# RZ/A1H register map
Vendor: Renesas
Registers are 32-bit, read-write, reset 0x0 unless marked. A register's access mark holds for its fields unless they carry their own. Offsets are from the block's base; [hi:lo] are bit positions; {n}, {i} and the like mark numbered series; 'fields as' and 'values as' point back to an identical list.

## INTC
Base 0xE8201000
0x00 ICDDCR
  [0] Enable
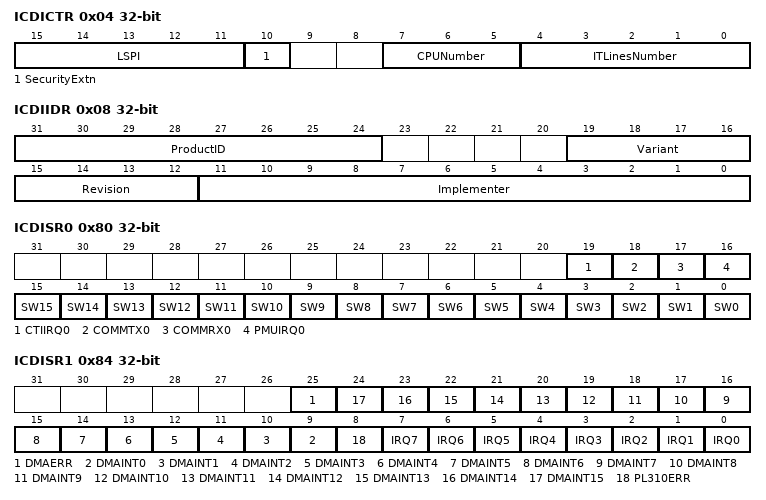
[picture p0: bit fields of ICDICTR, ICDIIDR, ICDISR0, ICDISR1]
0x04 ICDICTR
  [15:11] LSPI, [10] SecurityExtn, [7:5] CPUNumber, [4:0] ITLinesNumber
0x08 ICDIIDR
  [31:24] ProductID, [19:16] Variant, [15:12] Revision, [11:0] Implementer
0x80 ICDISR0
  [19] CTIIRQ0, [18] COMMTX0, [17] COMMRX0, [16] PMUIRQ0, [n] SW{n} (n=0..15)
0x84 ICDISR1
  [25] DMAERR, [n+9] DMAINT{n} (n=0..15), [8] PL310ERR, [n] IRQ{n} (n=0..7)
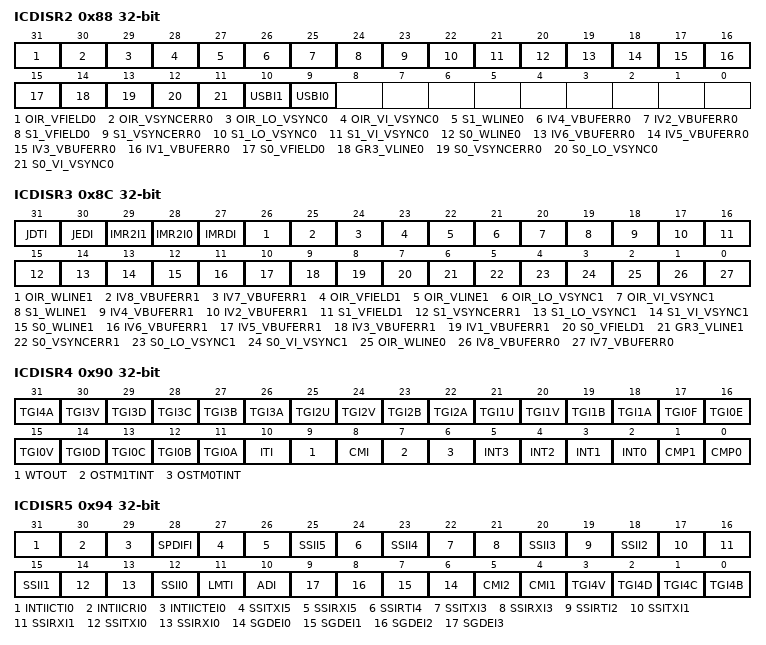
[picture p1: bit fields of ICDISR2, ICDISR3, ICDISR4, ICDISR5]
0x88 ICDISR2
  [31] OIR_VFIELD0, [30] OIR_VSYNCERR0, [29] OIR_LO_VSYNC0, [28] OIR_VI_VSYNC0, [27] S1_WLINE0, [26] IV4_VBUFERR0, [25] IV2_VBUFERR0, [24] S1_VFIELD0, [23] S1_VSYNCERR0, [22] S1_LO_VSYNC0, [21] S1_VI_VSYNC0, [20] S0_WLINE0, [19] IV6_VBUFERR0, [18] IV5_VBUFERR0, [17] IV3_VBUFERR0, [16] IV1_VBUFERR0, [15] S0_VFIELD0, [14] GR3_VLINE0, [13] S0_VSYNCERR0, [12] S0_LO_VSYNC0, [11] S0_VI_VSYNC0, [10] USBI1, [9] USBI0
0x8C ICDISR3
  [31] JDTI, [30] JEDI, [29] IMR2I1, [28] IMR2I0, [27] IMRDI, [26] OIR_WLINE1, [25] IV8_VBUFERR1, [24] IV7_VBUFERR1, [23] OIR_VFIELD1, [22] OIR_VLINE1, [21] OIR_LO_VSYNC1, [20] OIR_VI_VSYNC1, [19] S1_WLINE1, [18] IV4_VBUFERR1, [17] IV2_VBUFERR1, [16] S1_VFIELD1, [15] S1_VSYNCERR1, [14] S1_LO_VSYNC1, [13] S1_VI_VSYNC1, [12] S0_WLINE1, [11] IV6_VBUFERR1, [10] IV5_VBUFERR1, [9] IV3_VBUFERR1, [8] IV1_VBUFERR1, [7] S0_VFIELD1, [6] GR3_VLINE1, [5] S0_VSYNCERR1, [4] S0_LO_VSYNC1, [3] S0_VI_VSYNC1, [2] OIR_WLINE0, [1] IV8_VBUFERR0, [0] IV7_VBUFERR0
0x90 ICDISR4
  [31] TGI4A, [30] TGI3V, [29] TGI3D, [28] TGI3C, [27] TGI3B, [26] TGI3A, [25] TGI2U, [24] TGI2V, [23] TGI2B, [22] TGI2A, [21] TGI1U, [20] TGI1V, [19] TGI1B, [18] TGI1A, [17] TGI0F, [16] TGI0E, [15] TGI0V, [14] TGI0D, [13] TGI0C, [12] TGI0B, [11] TGI0A, [10] ITI, [9] WTOUT, [8] CMI, [7] OSTM1TINT, [6] OSTM0TINT, [n+2] INT{n} (n=0..3), [1] CMP1, [0] CMP0
0x94 ICDISR5
  [31] INTIICTI0, [30] INTIICRI0, [29] INTIICTEI0, [28] SPDIFI, [27] SSITXI5, [26] SSIRXI5, [25] SSII5, [24] SSIRTI4, [23] SSII4, [22] SSITXI3, [21] SSIRXI3, [20] SSII3, [19] SSIRTI2, [18] SSII2, [17] SSITXI1, [16] SSIRXI1, [15] SSII1, [14] SSITXI0, [13] SSIRXI0, [12] SSII0, [11] LMTI, [10] ADI, [n+6] SGDEI{n} (n=0..3), [5] CMI2, [4] CMI1, [3] TGI4V, [2] TGI4D, [1] TGI4C, [0] TGI4B
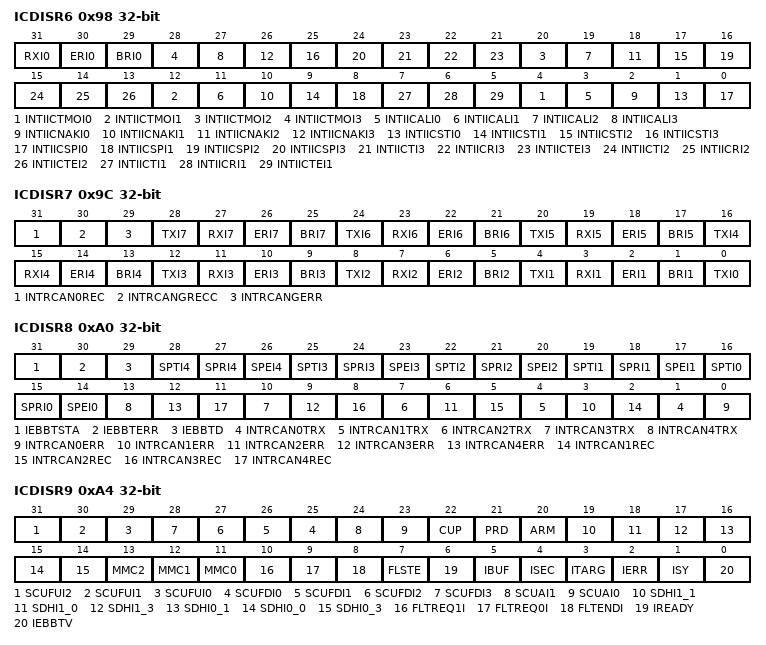
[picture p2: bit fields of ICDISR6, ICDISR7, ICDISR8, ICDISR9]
0x98 ICDISR6
  [31] RXI0, [30] ERI0, [29] BRI0, [8n+4] INTIICTMOI{n} (n=0..3), [8n+3] INTIICALI{n} (n=0..3), [8n+2] INTIICNAKI{n} (n=0..3), [8n+1] INTIICSTI{n} (n=0..3), [8n] INTIICSPI{n} (n=0..3), [23] INTIICTI3, [22] INTIICRI3, [21] INTIICTEI3, [15] INTIICTI2, [14] INTIICRI2, [13] INTIICTEI2, [7] INTIICTI1, [6] INTIICRI1, [5] INTIICTEI1
0x9C ICDISR7
  [31] INTRCAN0REC, [30] INTRCANGRECC, [29] INTRCANGERR, [4n] TXI{n} (n=0..7), [4n-1] RXI{n} (n=1..7), [4n-2] ERI{n} (n=1..7), [4n-3] BRI{n} (n=1..7)
0xA0 ICDISR8
  [31] IEBBTSTA, [30] IEBBTERR, [29] IEBBTD, [3n+16] SPTI{n} (n=0..4), [3n+15] SPRI{n} (n=0..4), [3n+14] SPEI{n} (n=0..4), [3n+1] INTRCAN{n}TRX (n=0..4), [3n] INTRCAN{n}ERR (n=0..4), [3n-1] INTRCAN{n}REC (n=1..4)
0xA4 ICDISR9
  [31] SCUFUI2, [30] SCUFUI1, [29] SCUFUI0, [n+25] SCUFDI{n} (n=0..3), [24] SCUAI1, [23] SCUAI0, [22] CUP, [21] PRD, [20] ARM, [19] SDHI1_1, [18] SDHI1_0, [17] SDHI1_3, [16] SDHI0_1, [15] SDHI0_0, [14] SDHI0_3, [13] MMC2, [12] MMC1, [11] MMC0, [10] FLTREQ1I, [9] FLTREQ0I, [8] FLTENDI, [7] FLSTE, [6] IREADY, [5] IBUF, [4] ISEC, [3] ITARG, [2] IERR, [1] ISY, [0] IEBBTV
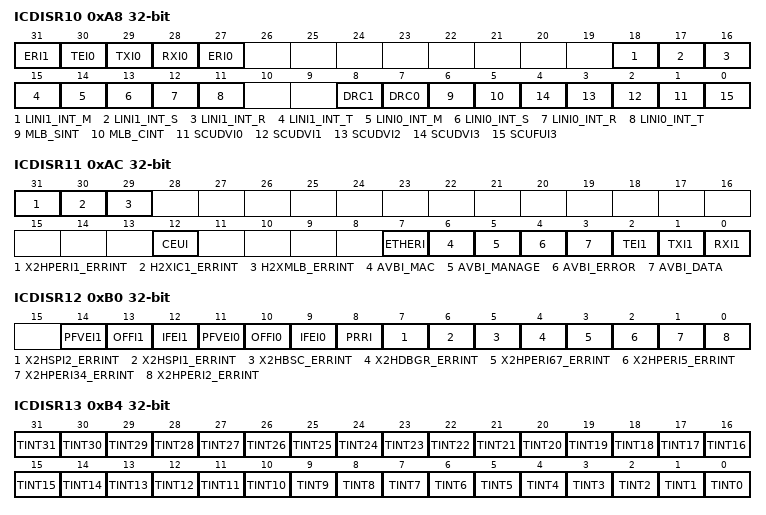
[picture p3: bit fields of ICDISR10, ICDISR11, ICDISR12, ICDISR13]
0xA8 ICDISR10
  [31] ERI1, [30] TEI0, [29] TXI0, [28] RXI0, [27] ERI0, [18] LINI1_INT_M, [17] LINI1_INT_S, [16] LINI1_INT_R, [15] LINI1_INT_T, [14] LINI0_INT_M, [13] LINI0_INT_S, [12] LINI0_INT_R, [11] LINI0_INT_T, [8] DRC1, [7] DRC0, [6] MLB_SINT, [5] MLB_CINT, [n+1] SCUDVI{n} (n=0..3), [0] SCUFUI3
0xAC ICDISR11
  [31] X2HPERI1_ERRINT, [30] H2XIC1_ERRINT, [29] H2XMLB_ERRINT, [12] CEUI, [7] ETHERI, [6] AVBI_MAC, [5] AVBI_MANAGE, [4] AVBI_ERROR, [3] AVBI_DATA, [2] TEI1, [1] TXI1, [0] RXI1
0xB0 ICDISR12
  [14] PFVEI1, [13] OFFI1, [12] IFEI1, [11] PFVEI0, [10] OFFI0, [9] IFEI0, [8] PRRI, [7] X2HSPI2_ERRINT, [6] X2HSPI1_ERRINT, [5] X2HBSC_ERRINT, [4] X2HDBGR_ERRINT, [3] X2HPERI67_ERRINT, [2] X2HPERI5_ERRINT, [1] X2HPERI34_ERRINT, [0] X2HPERI2_ERRINT
0xB4 ICDISR13
  [n] TINT{n} (n=0..31)
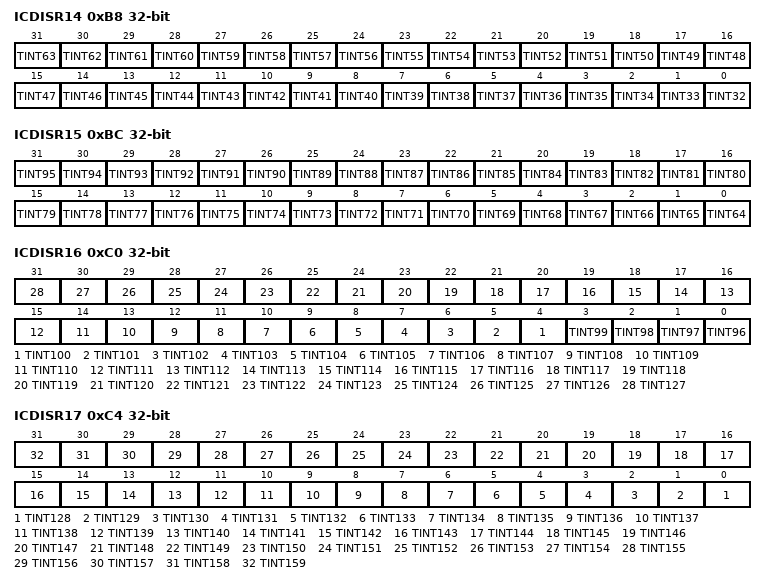
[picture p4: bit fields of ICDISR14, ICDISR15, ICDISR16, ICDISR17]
0xB8 ICDISR14
  [n-32] TINT{n} (n=32..63)
0xBC ICDISR15
  [n-64] TINT{n} (n=64..95)
0xC0 ICDISR16
  [n-96] TINT{n} (n=96..127)
0xC4 ICDISR17
  [n-128] TINT{n} (n=128..159)
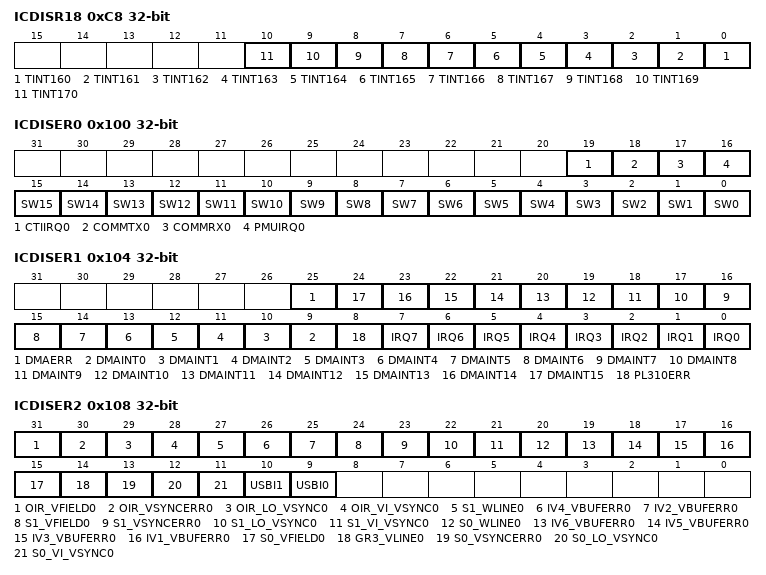
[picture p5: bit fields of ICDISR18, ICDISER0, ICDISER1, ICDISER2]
0xC8 ICDISR18
  [n-160] TINT{n} (n=160..170)
0x100 ICDISER0
  fields as ICDISR0
0x104 ICDISER1
  fields as ICDISR1
0x108 ICDISER2
  fields as ICDISR2
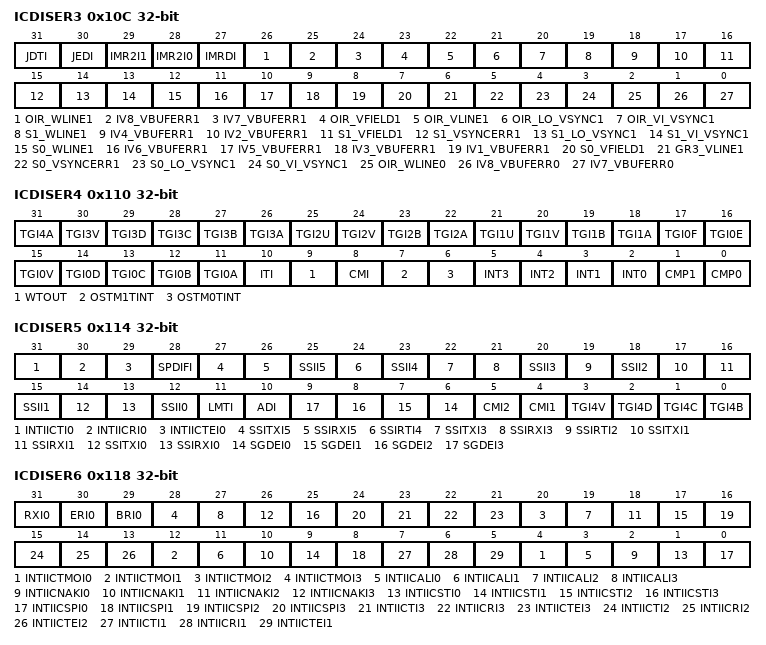
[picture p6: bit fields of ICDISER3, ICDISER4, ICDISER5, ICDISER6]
0x10C ICDISER3
  fields as ICDISR3
0x110 ICDISER4
  fields as ICDISR4
0x114 ICDISER5
  fields as ICDISR5
0x118 ICDISER6
  fields as ICDISR6
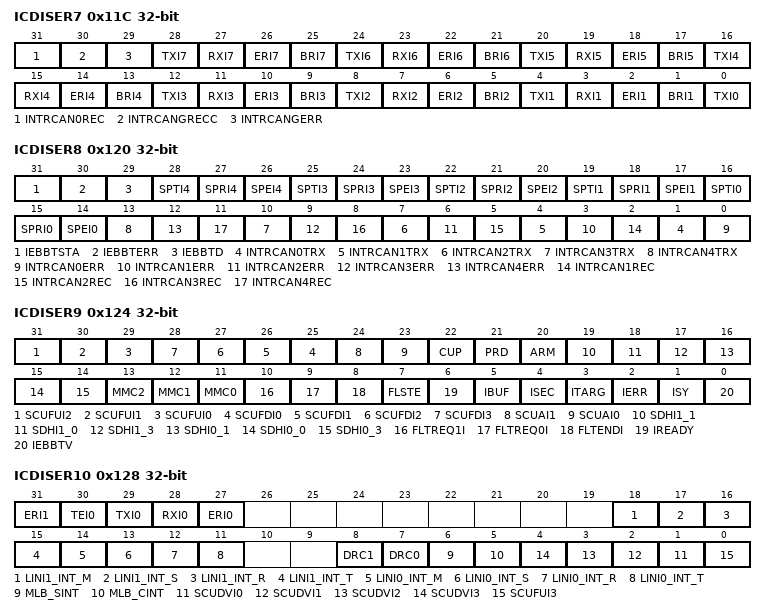
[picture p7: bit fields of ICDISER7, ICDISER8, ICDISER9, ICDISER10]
0x11C ICDISER7
  fields as ICDISR7
0x120 ICDISER8
  fields as ICDISR8
0x124 ICDISER9
  fields as ICDISR9
0x128 ICDISER10
  fields as ICDISR10
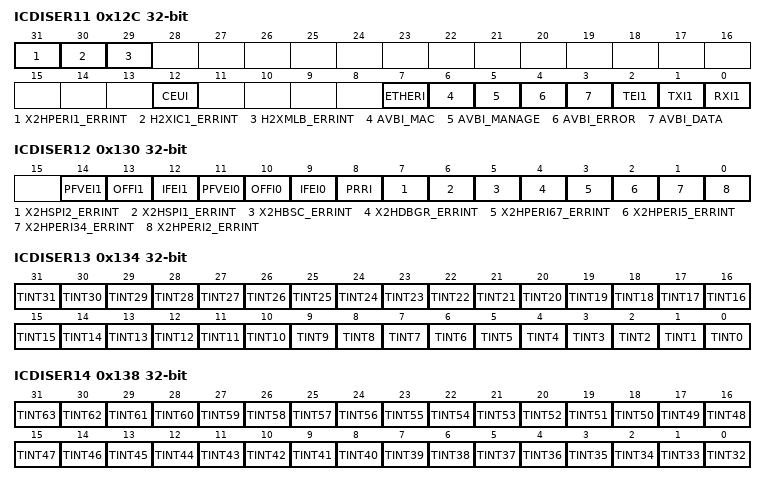
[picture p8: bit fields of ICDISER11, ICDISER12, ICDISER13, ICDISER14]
0x12C ICDISER11
  fields as ICDISR11
0x130 ICDISER12
  fields as ICDISR12
0x134 ICDISER13
  [n] TINT{n} (n=0..31)
0x138 ICDISER14
  [n-32] TINT{n} (n=32..63)
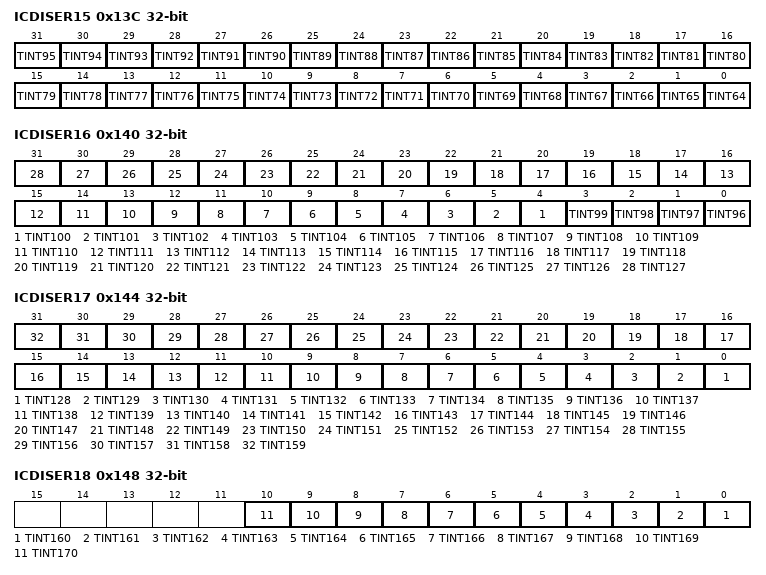
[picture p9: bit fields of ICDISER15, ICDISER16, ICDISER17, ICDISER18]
0x13C ICDISER15
  [n-64] TINT{n} (n=64..95)
0x140 ICDISER16
  [n-96] TINT{n} (n=96..127)
0x144 ICDISER17
  [n-128] TINT{n} (n=128..159)
0x148 ICDISER18
  [n-160] TINT{n} (n=160..170)
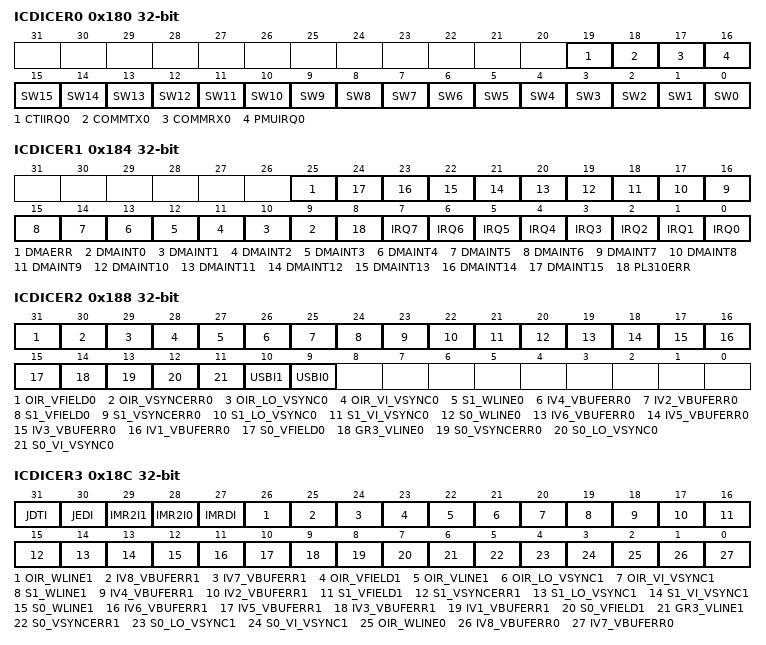
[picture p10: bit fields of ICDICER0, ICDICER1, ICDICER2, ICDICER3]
0x180 ICDICER0
  fields as ICDISR0
0x184 ICDICER1
  fields as ICDISR1
0x188 ICDICER2
  fields as ICDISR2
0x18C ICDICER3
  fields as ICDISR3
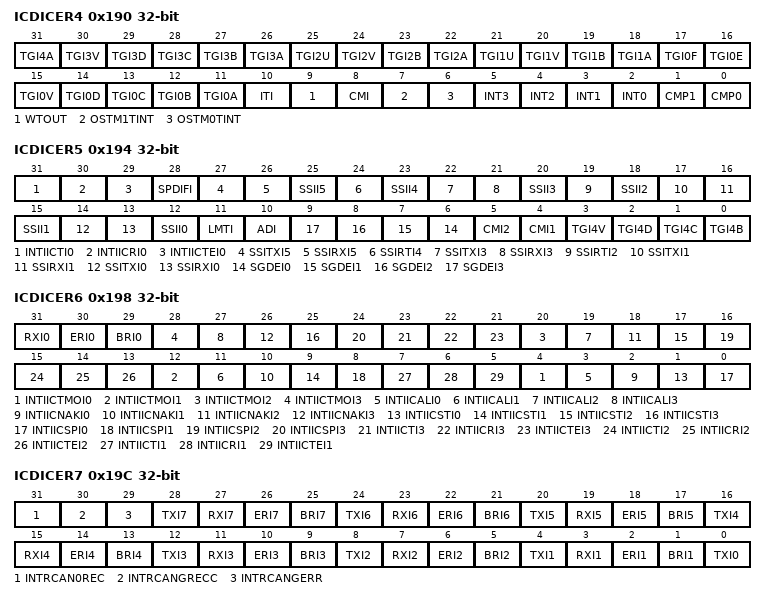
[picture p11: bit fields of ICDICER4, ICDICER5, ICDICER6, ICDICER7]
0x190 ICDICER4
  fields as ICDISR4
0x194 ICDICER5
  fields as ICDISR5
0x198 ICDICER6
  fields as ICDISR6
0x19C ICDICER7
  fields as ICDISR7
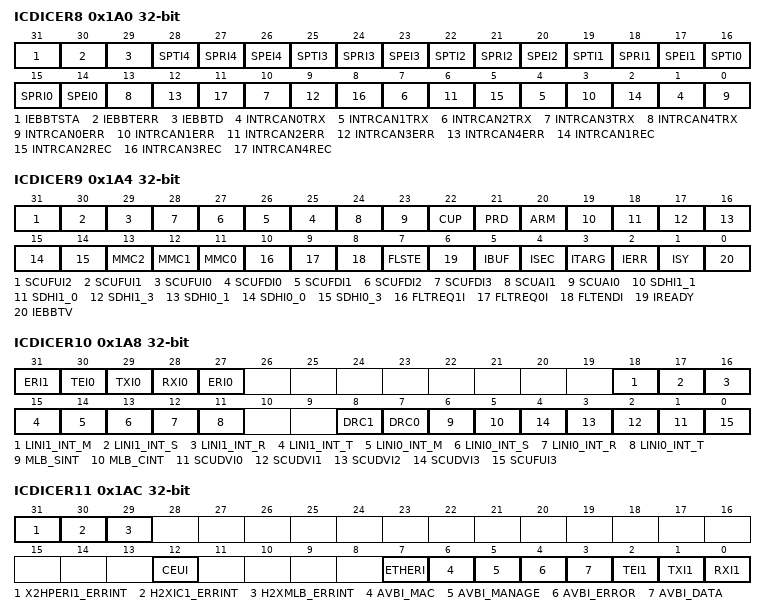
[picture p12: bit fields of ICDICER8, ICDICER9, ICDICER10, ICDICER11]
0x1A0 ICDICER8
  fields as ICDISR8
0x1A4 ICDICER9
  fields as ICDISR9
0x1A8 ICDICER10
  fields as ICDISR10
0x1AC ICDICER11
  fields as ICDISR11
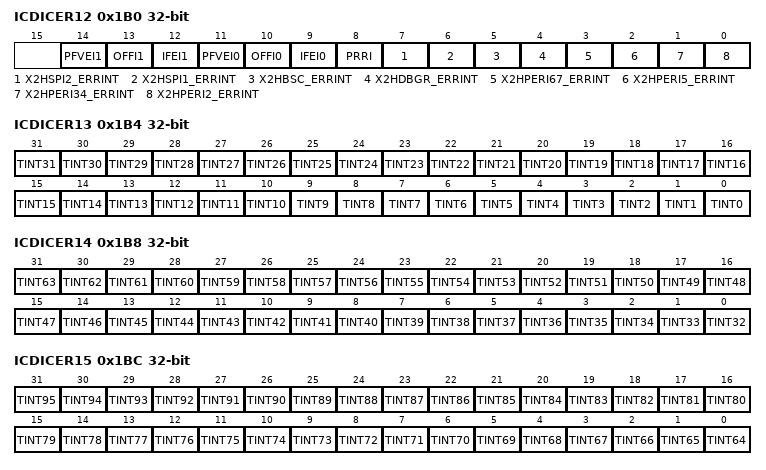
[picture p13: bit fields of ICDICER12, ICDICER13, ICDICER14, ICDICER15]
0x1B0 ICDICER12
  fields as ICDISR12
0x1B4 ICDICER13
  [n] TINT{n} (n=0..31)
0x1B8 ICDICER14
  [n-32] TINT{n} (n=32..63)
0x1BC ICDICER15
  [n-64] TINT{n} (n=64..95)
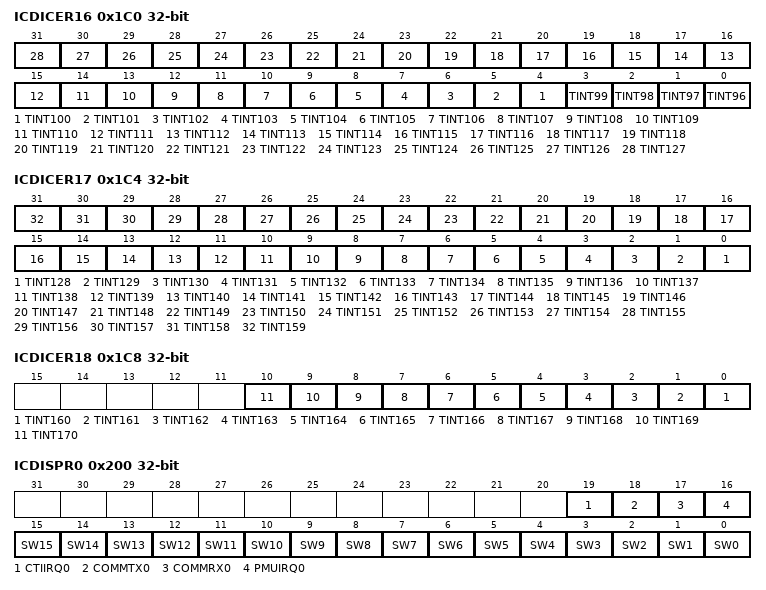
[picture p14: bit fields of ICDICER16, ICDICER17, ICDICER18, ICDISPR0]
0x1C0 ICDICER16
  [n-96] TINT{n} (n=96..127)
0x1C4 ICDICER17
  [n-128] TINT{n} (n=128..159)
0x1C8 ICDICER18
  [n-160] TINT{n} (n=160..170)
0x200 ICDISPR0
  fields as ICDISR0
0x204 ICDISPR1
  fields as ICDISR1
0x208 ICDISPR2
  fields as ICDISR2
0x20C ICDISPR3
  fields as ICDISR3
0x210 ICDISPR4
  fields as ICDISR4
0x214 ICDISPR5
  fields as ICDISR5
0x218 ICDISPR6
  fields as ICDISR6
0x21C ICDISPR7
  fields as ICDISR7
0x220 ICDISPR8
  fields as ICDISR8
0x224 ICDISPR9
  fields as ICDISR9
0x228 ICDISPR10
  fields as ICDISR10
0x22C ICDISPR11
  fields as ICDISR11
0x230 ICDISPR12
  fields as ICDISR12
0x234 ICDISPR13
  [n] TINT{n} (n=0..31)
0x238 ICDISPR14
  [n-32] TINT{n} (n=32..63)
0x23C ICDISPR15
  [n-64] TINT{n} (n=64..95)
0x240 ICDISPR16
  [n-96] TINT{n} (n=96..127)
0x244 ICDISPR17
  [n-128] TINT{n} (n=128..159)
0x248 ICDISPR18
  [n-160] TINT{n} (n=160..170)
0x280 ICDICPR0
  fields as ICDISR0
0x284 ICDICPR1
  fields as ICDISR1
0x288 ICDICPR2
  fields as ICDISR2
0x28C ICDICPR3
  fields as ICDISR3
0x290 ICDICPR4
  fields as ICDISR4
0x294 ICDICPR5
  fields as ICDISR5
0x298 ICDICPR6
  fields as ICDISR6
0x29C ICDICPR7
  fields as ICDISR7
0x2A0 ICDICPR8
  fields as ICDISR8
0x2A4 ICDICPR9
  fields as ICDISR9
0x2A8 ICDICPR10
  fields as ICDISR10
0x2AC ICDICPR11
  fields as ICDISR11
0x2B0 ICDICPR12
  fields as ICDISR12
0x2B4 ICDICPR13
  [n] TINT{n} (n=0..31)
0x2B8 ICDICPR14
  [n-32] TINT{n} (n=32..63)
0x2BC ICDICPR15
  [n-64] TINT{n} (n=64..95)
0x2C0 ICDICPR16
  [n-96] TINT{n} (n=96..127)
0x2C4 ICDICPR17
  [n-128] TINT{n} (n=128..159)
0x2C8 ICDICPR18
  [n-160] TINT{n} (n=160..170)
0x300 ICDABR0
  fields as ICDISR0
0x304 ICDABR1
  fields as ICDISR1
0x308 ICDABR2
  fields as ICDISR2
0x30C ICDABR3
  fields as ICDISR3
0x310 ICDABR4
  fields as ICDISR4
0x314 ICDABR5
  fields as ICDISR5
0x318 ICDABR6
  fields as ICDISR6
0x31C ICDABR7
  fields as ICDISR7
0x320 ICDABR8
  fields as ICDISR8
0x324 ICDABR9
  fields as ICDISR9
0x328 ICDABR10
  fields as ICDISR10
0x32C ICDABR11
  fields as ICDISR11
0x330 ICDABR12
  fields as ICDISR12
0x334 ICDABR13
  [n] TINT{n} (n=0..31)
0x338 ICDABR14
  [n-32] TINT{n} (n=32..63)
0x33C ICDABR15
  [n-64] TINT{n} (n=64..95)
0x340 ICDABR16
  [n-96] TINT{n} (n=96..127)
0x344 ICDABR17
  [n-128] TINT{n} (n=128..159)
0x348 ICDABR18
  [n-160] TINT{n} (n=160..170)
0x400 ICDIPR0
  [8n+7:8n] SW{n} (n=0..3)
0x404 ICDIPR1
  [8n-25:8n-32] SW{n} (n=4..7)
0x408 ICDIPR2
  [8n-57:8n-64] SW{n} (n=8..11)
0x40C ICDIPR3
  [8n-89:8n-96] SW{n} (n=12..15)
0x410 ICDIPR4
  [31:24] CTIIRQ0, [23:16] COMMTX0, [15:8] COMMRX0, [7:0] PMUIRQ0
{0x400+4i} ICDIPR{i} (i=5..7)
0x420 ICDIPR8
  [8n+7:8n] IRQ{n} (n=0..3)
0x424 ICDIPR9
  [8n-25:8n-32] IRQ{n} (n=4..7)
0x428 ICDIPR10
  [31:24] DMAINT2, [23:16] DMAINT1, [15:8] DMAINT0, [7:0] PL310ERR
0x42C ICDIPR11
  [8n-17:8n-24] DMAINT{n} (n=3..6)
0x430 ICDIPR12
  [8n-49:8n-56] DMAINT{n} (n=7..10)
0x434 ICDIPR13
  [8n-81:8n-88] DMAINT{n} (n=11..14)
0x438 ICDIPR14
  [15:8] DMAERR, [7:0] DMAINT15
{0x400+4i} ICDIPR{i} (i=15..17)
0x448 ICDIPR18
  [31:24] S0_VI_VSYNC0, [23:16] USBI1, [15:8] USBI0
0x44C ICDIPR19
  [31:24] S0_VFIELD0, [23:16] GR3_VLINE0, [15:8] S0_VSYNCERR0, [7:0] S0_LO_VSYNC0
0x450 ICDIPR20
  [31:24] IV6_VBUFERR0, [23:16] IV5_VBUFERR0, [15:8] IV3_VBUFERR0, [7:0] IV1_VBUFERR0
0x454 ICDIPR21
  [31:24] S1_VSYNCERR0, [23:16] S1_LO_VSYNC0, [15:8] S1_VI_VSYNC0, [7:0] S0_WLINE0
0x458 ICDIPR22
  [31:24] S1_WLINE0, [23:16] IV4_VBUFERR0, [15:8] IV2_VBUFERR0, [7:0] S1_VFIELD0
0x45C ICDIPR23
  [31:24] OIR_VFIELD0, [23:16] OIR_VSYNCERR0, [15:8] OIR_LO_VSYNC0, [7:0] OIR_VI_VSYNC0
0x460 ICDIPR24
  [31:24] S0_VI_VSYNC1, [23:16] OIR_WLINE0, [15:8] IV8_VBUFERR0, [7:0] IV7_VBUFERR0
0x464 ICDIPR25
  [31:24] S0_VFIELD1, [23:16] GR3_VLINE1, [15:8] S0_VSYNCERR1, [7:0] S0_LO_VSYNC1
0x468 ICDIPR26
  [31:24] IV6_VBUFERR1, [23:16] IV5_VBUFERR1, [15:8] IV3_VBUFERR1, [7:0] IV1_VBUFERR1
0x46C ICDIPR27
  [31:24] S1_VSYNCERR1, [23:16] S1_LO_VSYNC1, [15:8] S1_VI_VSYNC1, [7:0] S0_WLINE1
0x470 ICDIPR28
  [31:24] S1_WLINE1, [23:16] IV4_VBUFERR1, [15:8] IV2_VBUFERR1, [7:0] S1_VFIELD1
0x474 ICDIPR29
  [31:24] OIR_VFIELD1, [23:16] OIR_VLINE1, [15:8] OIR_LO_VSYNC1, [7:0] OIR_VI_VSYNC1
0x478 ICDIPR30
  [31:24] IMRDI, [23:16] OIR_WLINE1, [15:8] IV8_VBUFERR1, [7:0] IV7_VBUFERR1
0x47C ICDIPR31
  [31:24] JDTI, [23:16] JEDI, [15:8] IMR2I1, [7:0] IMR2I0
0x480 ICDIPR32
  [31:24] INT1, [23:16] INT0, [15:8] CMP1, [7:0] CMP0
0x484 ICDIPR33
  [31:24] OSTM1TINT, [23:16] OSTM0TINT, [15:8] INT3, [7:0] INT2
0x488 ICDIPR34
  [31:24] TGI0A, [23:16] ITI, [15:8] WTOUT, [7:0] CMI
0x48C ICDIPR35
  [31:24] TGI0V, [23:16] TGI0D, [15:8] TGI0C, [7:0] TGI0B
0x490 ICDIPR36
  [31:24] TGI1B, [23:16] TGI1A, [15:8] TGI0F, [7:0] TGI0E
0x494 ICDIPR37
  [31:24] TGI2B, [23:16] TGI2A, [15:8] TGI1U, [7:0] TGI1V
0x498 ICDIPR38
  [31:24] TGI3B, [23:16] TGI3A, [15:8] TGI2U, [7:0] TGI2V
0x49C ICDIPR39
  [31:24] TGI4A, [23:16] TGI3V, [15:8] TGI3D, [7:0] TGI3C
0x4A0 ICDIPR40
  [31:24] TGI4V, [23:16] TGI4D, [15:8] TGI4C, [7:0] TGI4B
0x4A4 ICDIPR41
  [31:24] SGDEI1, [23:16] SGDEI0, [15:8] CMI2, [7:0] CMI1
0x4A8 ICDIPR42
  [31:24] LMTI, [23:16] ADI, [15:8] SGDEI3, [7:0] SGDEI2
0x4AC ICDIPR43
  [31:24] SSII1, [23:16] SSITXI0, [15:8] SSIRXI0, [7:0] SSII0
0x4B0 ICDIPR44
  [31:24] SSIRTI2, [23:16] SSII2, [15:8] SSITXI1, [7:0] SSIRXI1
0x4B4 ICDIPR45
  [31:24] SSII4, [23:16] SSITXI3, [15:8] SSIRXI3, [7:0] SSII3
0x4B8 ICDIPR46
  [31:24] SSITXI5, [23:16] SSIRXI5, [15:8] SSII5, [7:0] SSIRTI4
0x4BC ICDIPR47
  [31:24] INTIICTI0, [23:16] INTIICRI0, [15:8] INTIICTEI0, [7:0] SPDIFI
0x4C0 ICDIPR48
  [31:24] INTIICALI0, [23:16] INTIICNAKI0, [15:8] INTIICSTI0, [7:0] INTIICSPI0
0x4C4 ICDIPR49
  [31:24] INTIICTI1, [23:16] INTIICRI1, [15:8] INTIICTEI1, [7:0] INTIICTMOI0
0x4C8 ICDIPR50
  [31:24] INTIICALI1, [23:16] INTIICNAKI1, [15:8] INTIICSTI1, [7:0] INTIICSPI1
0x4CC ICDIPR51
  [31:24] INTIICTI2, [23:16] INTIICRI2, [15:8] INTIICTEI2, [7:0] INTIICTMOI1
0x4D0 ICDIPR52
  [31:24] INTIICALI2, [23:16] INTIICNAKI2, [15:8] INTIICSTI2, [7:0] INTIICSPI2
0x4D4 ICDIPR53
  [31:24] INTIICTI3, [23:16] INTIICRI3, [15:8] INTIICTEI3, [7:0] INTIICTMOI2
0x4D8 ICDIPR54
  [31:24] INTIICALI3, [23:16] INTIICNAKI3, [15:8] INTIICSTI3, [7:0] INTIICSPI3
0x4DC ICDIPR55
  [31:24] RXI0, [23:16] ERI0, [15:8] BRI0, [7:0] INTIICTMOI3
{0x400+4i} ICDIPR{i} (i=56..62)
  [31:24] RXI{i-55}, [23:16] ERI{i-55}, [15:8] BRI{i-55}, [7:0] TXI{i-56}
0x4FC ICDIPR63
  [31:24] INTRCAN0REC, [23:16] INTRCANGRECC, [15:8] INTRCANGERR, [7:0] TXI7
0x500 ICDIPR64
  [31:24] INTRCAN1ERR, [23:16] INTRCAN1REC, [15:8] INTRCAN0TRX, [7:0] INTRCAN0ERR
0x504 ICDIPR65
  [31:24] INTRCAN2TRX, [23:16] INTRCAN2ERR, [15:8] INTRCAN2REC, [7:0] INTRCAN1TRX
0x508 ICDIPR66
  [31:24] INTRCAN4REC, [23:16] INTRCAN3TRX, [15:8] INTRCAN3ERR, [7:0] INTRCAN3REC
0x50C ICDIPR67
  [31:24] SPRI0, [23:16] SPEI0, [15:8] INTRCAN4TRX, [7:0] INTRCAN4ERR
0x510 ICDIPR68
  [31:24] SPTI1, [23:16] SPRI1, [15:8] SPEI1, [7:0] SPTI0
0x514 ICDIPR69
  [31:24] SPEI3, [23:16] SPTI2, [15:8] SPRI2, [7:0] SPEI2
0x518 ICDIPR70
  [31:24] SPRI4, [23:16] SPEI4, [15:8] SPTI3, [7:0] SPRI3
0x51C ICDIPR71
  [31:24] IEBBTSTA, [23:16] IEBBTERR, [15:8] IEBBTD, [7:0] SPTI4
0x520 ICDIPR72
  [31:24] ITARG, [23:16] IERR, [15:8] ISY, [7:0] IEBBTV
0x524 ICDIPR73
  [31:24] FLSTE, [23:16] IREADY, [15:8] IBUF, [7:0] ISEC
0x528 ICDIPR74
  [31:24] MMC0, [23:16] FLTREQ1I, [15:8] FLTREQ0I, [7:0] FLTENDI
0x52C ICDIPR75
  [31:24] SDHI0_0, [23:16] SDHI0_3, [15:8] MMC2, [7:0] MMC1
0x530 ICDIPR76
  [31:24] SDHI1_1, [23:16] SDHI1_0, [15:8] SDHI1_3, [7:0] SDHI0_1
0x534 ICDIPR77
  [31:24] SCUAI0, [23:16] CUP, [15:8] PRD, [7:0] ARM
0x538 ICDIPR78
  [31:24] SCUFDI2, [23:16] SCUFDI1, [15:8] SCUFDI0, [7:0] SCUAI1
0x53C ICDIPR79
  [31:24] SCUFUI2, [23:16] SCUFUI1, [15:8] SCUFUI0, [7:0] SCUFDI3
0x540 ICDIPR80
  [31:24] SCUDVI2, [23:16] SCUDVI1, [15:8] SCUDVI0, [7:0] SCUFUI3
0x544 ICDIPR81
  [31:24] DRC0, [23:16] MLB_SINT, [15:8] MLB_CINT, [7:0] SCUDVI3
0x548 ICDIPR82
  [31:24] LINI0_INT_T, [7:0] DRC1
0x54C ICDIPR83
  [31:24] LINI1_INT_T, [23:16] LINI0_INT_M, [15:8] LINI0_INT_S, [7:0] LINI0_INT_R
0x550 ICDIPR84
  [23:16] LINI1_INT_M, [15:8] LINI1_INT_S, [7:0] LINI1_INT_R
0x554 ICDIPR85
0x558 ICDIPR86
  [31:24] ERI0
0x55C ICDIPR87
  [31:24] ERI1, [23:16] TEI0, [15:8] TXI0, [7:0] RXI0
0x560 ICDIPR88
  [31:24] AVBI_DATA, [23:16] TEI1, [15:8] TXI1, [7:0] RXI1
0x564 ICDIPR89
  [31:24] ETHERI, [23:16] AVBI_MAC, [15:8] AVBI_MANAGE, [7:0] AVBI_ERROR
0x568 ICDIPR90
0x56C ICDIPR91
  [7:0] CEUI
{0x400+4i} ICDIPR{i} (i=92..94)
0x57C ICDIPR95
  [31:24] X2HPERI1_ERRINT, [23:16] H2XIC1_ERRINT, [15:8] H2XMLB_ERRINT
0x580 ICDIPR96
  [31:24] X2HPERI67_ERRINT, [23:16] X2HPERI5_ERRINT, [15:8] X2HPERI34_ERRINT, [7:0] X2HPERI2_ERRINT
0x584 ICDIPR97
  [31:24] X2HSPI2_ERRINT, [23:16] X2HSPI1_ERRINT, [15:8] X2HBSC_ERRINT, [7:0] X2HDBGR_ERRINT
0x588 ICDIPR98
  [31:24] PFVEI0, [23:16] OFFI0, [15:8] IFEI0, [7:0] PRRI
0x58C ICDIPR99
  [23:16] PFVEI1, [15:8] OFFI1, [7:0] IFEI1
{0x400+4i} ICDIPR{i} (i=100..103)
0x5A0 ICDIPR104
  [8n+7:8n] TINT{n} (n=0..3)
0x5A4 ICDIPR105
  [8n-25:8n-32] TINT{n} (n=4..7)
0x5A8 ICDIPR106
  [8n-57:8n-64] TINT{n} (n=8..11)
0x5AC ICDIPR107
  [8n-89:8n-96] TINT{n} (n=12..15)
0x5B0 ICDIPR108
  [8n-121:8n-128] TINT{n} (n=16..19)
0x5B4 ICDIPR109
  [8n-153:8n-160] TINT{n} (n=20..23)
0x5B8 ICDIPR110
  [8n-185:8n-192] TINT{n} (n=24..27)
0x5BC ICDIPR111
  [8n-217:8n-224] TINT{n} (n=28..31)
0x5C0 ICDIPR112
  [8n-249:8n-256] TINT{n} (n=32..35)
0x5C4 ICDIPR113
  [8n-281:8n-288] TINT{n} (n=36..39)
0x5C8 ICDIPR114
  [8n-313:8n-320] TINT{n} (n=40..43)
0x5CC ICDIPR115
  [8n-345:8n-352] TINT{n} (n=44..47)
0x5D0 ICDIPR116
  [8n-377:8n-384] TINT{n} (n=48..51)
0x5D4 ICDIPR117
  [8n-409:8n-416] TINT{n} (n=52..55)
0x5D8 ICDIPR118
  [8n-441:8n-448] TINT{n} (n=56..59)
0x5DC ICDIPR119
  [8n-473:8n-480] TINT{n} (n=60..63)
0x5E0 ICDIPR120
  [8n-505:8n-512] TINT{n} (n=64..67)
0x5E4 ICDIPR121
  [8n-537:8n-544] TINT{n} (n=68..71)
0x5E8 ICDIPR122
  [8n-569:8n-576] TINT{n} (n=72..75)
0x5EC ICDIPR123
  [8n-601:8n-608] TINT{n} (n=76..79)
0x5F0 ICDIPR124
  [8n-633:8n-640] TINT{n} (n=80..83)
0x5F4 ICDIPR125
  [8n-665:8n-672] TINT{n} (n=84..87)
0x5F8 ICDIPR126
  [8n-697:8n-704] TINT{n} (n=88..91)
0x5FC ICDIPR127
  [8n-729:8n-736] TINT{n} (n=92..95)
0x600 ICDIPR128
  [8n-761:8n-768] TINT{n} (n=96..99)
0x604 ICDIPR129
  [8n-793:8n-800] TINT{n} (n=100..103)
0x608 ICDIPR130
  [8n-825:8n-832] TINT{n} (n=104..107)
0x60C ICDIPR131
  [8n-857:8n-864] TINT{n} (n=108..111)
0x610 ICDIPR132
  [8n-889:8n-896] TINT{n} (n=112..115)
0x614 ICDIPR133
  [8n-921:8n-928] TINT{n} (n=116..119)
0x618 ICDIPR134
  [8n-953:8n-960] TINT{n} (n=120..123)
0x61C ICDIPR135
  [8n-985:8n-992] TINT{n} (n=124..127)
0x620 ICDIPR136
  [8n-1017:8n-1024] TINT{n} (n=128..131)
0x624 ICDIPR137
  [8n-1049:8n-1056] TINT{n} (n=132..135)
0x628 ICDIPR138
  [8n-1081:8n-1088] TINT{n} (n=136..139)
0x62C ICDIPR139
  [8n-1113:8n-1120] TINT{n} (n=140..143)
0x630 ICDIPR140
  [8n-1145:8n-1152] TINT{n} (n=144..147)
0x634 ICDIPR141
  [8n-1177:8n-1184] TINT{n} (n=148..151)
0x638 ICDIPR142
  [8n-1209:8n-1216] TINT{n} (n=152..155)
0x63C ICDIPR143
  [8n-1241:8n-1248] TINT{n} (n=156..159)
0x640 ICDIPR144
  [8n-1273:8n-1280] TINT{n} (n=160..163)
0x644 ICDIPR145
  [8n-1305:8n-1312] TINT{n} (n=164..167)
0x648 ICDIPR146
  [23:16] TINT170, [15:8] TINT169, [7:0] TINT168
0x800 ICDIPTR0
  [8n+7:8n] SW{n} (n=0..3)
0x804 ICDIPTR1
  [8n-25:8n-32] SW{n} (n=4..7)
0x808 ICDIPTR2
  [8n-57:8n-64] SW{n} (n=8..11)
0x80C ICDIPTR3
  [8n-89:8n-96] SW{n} (n=12..15)
0x810 ICDIPTR4
  [31:24] CTIIRQ0, [23:16] COMMTX0, [15:8] COMMRX0, [7:0] PMUIRQ0
{0x800+4i} ICDIPTR{i} (i=5..7)
0x820 ICDIPTR8
  [8n+7:8n] IRQ{n} (n=0..3)
0x824 ICDIPTR9
  [8n-25:8n-32] IRQ{n} (n=4..7)
0x828 ICDIPTR10
  [31:24] DMAINT2, [23:16] DMAINT1, [15:8] DMAINT0, [7:0] PL310ERR
0x82C ICDIPTR11
  [8n-17:8n-24] DMAINT{n} (n=3..6)
0x830 ICDIPTR12
  [8n-49:8n-56] DMAINT{n} (n=7..10)
0x834 ICDIPTR13
  [8n-81:8n-88] DMAINT{n} (n=11..14)
0x838 ICDIPTR14
  [15:8] DMAERR, [7:0] DMAINT15
{0x800+4i} ICDIPTR{i} (i=15..17)
0x848 ICDIPTR18
  [31:24] S0_VI_VSYNC0, [23:16] USBI1, [15:8] USBI0
0x84C ICDIPTR19
  fields as ICDIPR19
0x850 ICDIPTR20
  fields as ICDIPR20
0x854 ICDIPTR21
  fields as ICDIPR21
0x858 ICDIPTR22
  fields as ICDIPR22
0x85C ICDIPTR23
  fields as ICDIPR23
0x860 ICDIPTR24
  fields as ICDIPR24
0x864 ICDIPTR25
  fields as ICDIPR25
0x868 ICDIPTR26
  fields as ICDIPR26
0x86C ICDIPTR27
  fields as ICDIPR27
0x870 ICDIPTR28
  fields as ICDIPR28
0x874 ICDIPTR29
  fields as ICDIPR29
0x878 ICDIPTR30
  fields as ICDIPR30
0x87C ICDIPTR31
  [31:24] JDTI, [23:16] JEDI, [15:8] IMR2I1, [7:0] IMR2I0
0x880 ICDIPTR32
  [31:24] INT1, [23:16] INT0, [15:8] CMP1, [7:0] CMP0
0x884 ICDIPTR33
  [31:24] OSTM1TINT, [23:16] OSTM0TINT, [15:8] INT3, [7:0] INT2
0x888 ICDIPTR34
  [31:24] TGI0A, [23:16] ITI, [15:8] WTOUT, [7:0] CMI
0x88C ICDIPTR35
  [31:24] TGI0V, [23:16] TGI0D, [15:8] TGI0C, [7:0] TGI0B
0x890 ICDIPTR36
  [31:24] TGI1B, [23:16] TGI1A, [15:8] TGI0F, [7:0] TGI0E
0x894 ICDIPTR37
  [31:24] TGI2B, [23:16] TGI2A, [15:8] TGI1U, [7:0] TGI1V
0x898 ICDIPTR38
  [31:24] TGI3B, [23:16] TGI3A, [15:8] TGI2U, [7:0] TGI2V
0x89C ICDIPTR39
  [31:24] TGI4A, [23:16] TGI3V, [15:8] TGI3D, [7:0] TGI3C
0x8A0 ICDIPTR40
  [31:24] TGI4V, [23:16] TGI4D, [15:8] TGI4C, [7:0] TGI4B
0x8A4 ICDIPTR41
  [31:24] SGDEI1, [23:16] SGDEI0, [15:8] CMI2, [7:0] CMI1
0x8A8 ICDIPTR42
  [31:24] LMTI, [23:16] ADI, [15:8] SGDEI3, [7:0] SGDEI2
0x8AC ICDIPTR43
  [31:24] SSII1, [23:16] SSITXI0, [15:8] SSIRXI0, [7:0] SSII0
0x8B0 ICDIPTR44
  [31:24] SSIRTI2, [23:16] SSII2, [15:8] SSITXI1, [7:0] SSIRXI1
0x8B4 ICDIPTR45
  [31:24] SSII4, [23:16] SSITXI3, [15:8] SSIRXI3, [7:0] SSII3
0x8B8 ICDIPTR46
  [31:24] SSITXI5, [23:16] SSIRXI5, [15:8] SSII5, [7:0] SSIRTI4
0x8BC ICDIPTR47
  fields as ICDIPR47
0x8C0 ICDIPTR48
  fields as ICDIPR48
0x8C4 ICDIPTR49
  fields as ICDIPR49
0x8C8 ICDIPTR50
  fields as ICDIPR50
0x8CC ICDIPTR51
  fields as ICDIPR51
0x8D0 ICDIPTR52
  fields as ICDIPR52
0x8D4 ICDIPTR53
  fields as ICDIPR53
0x8D8 ICDIPTR54
  fields as ICDIPR54
0x8DC ICDIPTR55
  [31:24] RXI0, [23:16] ERI0, [15:8] BRI0, [7:0] INTIICTMOI3
{0x800+4i} ICDIPTR{i} (i=56..62)
  fields as ICDIPR56
0x8FC ICDIPTR63
  fields as ICDIPR63
0x900 ICDIPTR64
  fields as ICDIPR64
0x904 ICDIPTR65
  fields as ICDIPR65
0x908 ICDIPTR66
  fields as ICDIPR66
0x90C ICDIPTR67
  [31:24] SPRI0, [23:16] SPEI0, [15:8] INTRCAN4TRX, [7:0] INTRCAN4ERR
0x910 ICDIPTR68
  [31:24] SPTI1, [23:16] SPRI1, [15:8] SPEI1, [7:0] SPTI0
0x914 ICDIPTR69
  [31:24] SPEI3, [23:16] SPTI2, [15:8] SPRI2, [7:0] SPEI2
0x918 ICDIPTR70
  [31:24] SPRI4, [23:16] SPEI4, [15:8] SPTI3, [7:0] SPRI3
0x91C ICDIPTR71
  [31:24] IEBBTSTA, [23:16] IEBBTERR, [15:8] IEBBTD, [7:0] SPTI4
0x920 ICDIPTR72
  [31:24] ITARG, [23:16] IERR, [15:8] ISY, [7:0] IEBBTV
0x924 ICDIPTR73
  [31:24] FLSTE, [23:16] IREADY, [15:8] IBUF, [7:0] ISEC
0x928 ICDIPTR74
  [31:24] MMC0, [23:16] FLTREQ1I, [15:8] FLTREQ0I, [7:0] FLTENDI
0x92C ICDIPTR75
  [31:24] SDHI0_0, [23:16] SDHI0_3, [15:8] MMC2, [7:0] MMC1
0x930 ICDIPTR76
  [31:24] SDHI1_1, [23:16] SDHI1_0, [15:8] SDHI1_3, [7:0] SDHI0_1
0x934 ICDIPTR77
  [31:24] SCUAI0, [23:16] CUP, [15:8] PRD, [7:0] ARM
0x938 ICDIPTR78
  [31:24] SCUFDI2, [23:16] SCUFDI1, [15:8] SCUFDI0, [7:0] SCUAI1
0x93C ICDIPTR79
  [31:24] SCUFUI2, [23:16] SCUFUI1, [15:8] SCUFUI0, [7:0] SCUFDI3
0x940 ICDIPTR80
  [31:24] SCUDVI2, [23:16] SCUDVI1, [15:8] SCUDVI0, [7:0] SCUFUI3
0x944 ICDIPTR81
  [31:24] DRC0, [23:16] MLB_SINT, [15:8] MLB_CINT, [7:0] SCUDVI3
0x948 ICDIPTR82
  [31:24] LINI0_INT_T, [7:0] DRC1
0x94C ICDIPTR83
  fields as ICDIPR83
0x950 ICDIPTR84
  [23:16] LINI1_INT_M, [15:8] LINI1_INT_S, [7:0] LINI1_INT_R
0x954 ICDIPTR85
0x958 ICDIPTR86
  [31:24] ERI0
0x95C ICDIPTR87
  [31:24] ERI1, [23:16] TEI0, [15:8] TXI0, [7:0] RXI0
0x960 ICDIPTR88
  [31:24] AVBI_DATA, [23:16] TEI1, [15:8] TXI1, [7:0] RXI1
0x964 ICDIPTR89
  fields as ICDIPR89
0x968 ICDIPTR90
0x96C ICDIPTR91
  [7:0] CEUI
{0x800+4i} ICDIPTR{i} (i=92..94)
0x97C ICDIPTR95
  [31:24] X2HPERI1_ERRINT, [23:16] H2XIC1_ERRINT, [15:8] H2XMLB_ERRINT
0x980 ICDIPTR96
  fields as ICDIPR96
0x984 ICDIPTR97
  fields as ICDIPR97
0x988 ICDIPTR98
  [31:24] PFVEI0, [23:16] OFFI0, [15:8] IFEI0, [7:0] PRRI
0x98C ICDIPTR99
  [23:16] PFVEI1, [15:8] OFFI1, [7:0] IFEI1
{0x800+4i} ICDIPTR{i} (i=100..103)
0x9A0 ICDIPTR104
  [8n+7:8n] TINT{n} (n=0..3)
0x9A4 ICDIPTR105
  [8n-25:8n-32] TINT{n} (n=4..7)
0x9A8 ICDIPTR106
  [8n-57:8n-64] TINT{n} (n=8..11)
0x9AC ICDIPTR107
  [8n-89:8n-96] TINT{n} (n=12..15)
0x9B0 ICDIPTR108
  [8n-121:8n-128] TINT{n} (n=16..19)
0x9B4 ICDIPTR109
  [8n-153:8n-160] TINT{n} (n=20..23)
0x9B8 ICDIPTR110
  [8n-185:8n-192] TINT{n} (n=24..27)
0x9BC ICDIPTR111
  [8n-217:8n-224] TINT{n} (n=28..31)
0x9C0 ICDIPTR112
  [8n-249:8n-256] TINT{n} (n=32..35)
0x9C4 ICDIPTR113
  [8n-281:8n-288] TINT{n} (n=36..39)
0x9C8 ICDIPTR114
  [8n-313:8n-320] TINT{n} (n=40..43)
0x9CC ICDIPTR115
  [8n-345:8n-352] TINT{n} (n=44..47)
0x9D0 ICDIPTR116
  [8n-377:8n-384] TINT{n} (n=48..51)
0x9D4 ICDIPTR117
  [8n-409:8n-416] TINT{n} (n=52..55)
0x9D8 ICDIPTR118
  [8n-441:8n-448] TINT{n} (n=56..59)
0x9DC ICDIPTR119
  [8n-473:8n-480] TINT{n} (n=60..63)
0x9E0 ICDIPTR120
  [8n-505:8n-512] TINT{n} (n=64..67)
0x9E4 ICDIPTR121
  [8n-537:8n-544] TINT{n} (n=68..71)
0x9E8 ICDIPTR122
  [8n-569:8n-576] TINT{n} (n=72..75)
0x9EC ICDIPTR123
  [8n-601:8n-608] TINT{n} (n=76..79)
0x9F0 ICDIPTR124
  [8n-633:8n-640] TINT{n} (n=80..83)
0x9F4 ICDIPTR125
  [8n-665:8n-672] TINT{n} (n=84..87)
0x9F8 ICDIPTR126
  [8n-697:8n-704] TINT{n} (n=88..91)
0x9FC ICDIPTR127
  [8n-729:8n-736] TINT{n} (n=92..95)
0xA00 ICDIPTR128
  [8n-761:8n-768] TINT{n} (n=96..99)
0xA04 ICDIPTR129
  [8n-793:8n-800] TINT{n} (n=100..103)
0xA08 ICDIPTR130
  [8n-825:8n-832] TINT{n} (n=104..107)
0xA0C ICDIPTR131
  [8n-857:8n-864] TINT{n} (n=108..111)
0xA10 ICDIPTR132
  [8n-889:8n-896] TINT{n} (n=112..115)
0xA14 ICDIPTR133
  [8n-921:8n-928] TINT{n} (n=116..119)
0xA18 ICDIPTR134
  [8n-953:8n-960] TINT{n} (n=120..123)
0xA1C ICDIPTR135
  [8n-985:8n-992] TINT{n} (n=124..127)
0xA20 ICDIPTR136
  [8n-1017:8n-1024] TINT{n} (n=128..131)
0xA24 ICDIPTR137
  [8n-1049:8n-1056] TINT{n} (n=132..135)
0xA28 ICDIPTR138
  [8n-1081:8n-1088] TINT{n} (n=136..139)
0xA2C ICDIPTR139
  [8n-1113:8n-1120] TINT{n} (n=140..143)
0xA30 ICDIPTR140
  [8n-1145:8n-1152] TINT{n} (n=144..147)
0xA34 ICDIPTR141
  [8n-1177:8n-1184] TINT{n} (n=148..151)
0xA38 ICDIPTR142
  [8n-1209:8n-1216] TINT{n} (n=152..155)
0xA3C ICDIPTR143
  [8n-1241:8n-1248] TINT{n} (n=156..159)
0xA40 ICDIPTR144
  [8n-1273:8n-1280] TINT{n} (n=160..163)
0xA44 ICDIPTR145
  [8n-1305:8n-1312] TINT{n} (n=164..167)
0xA48 ICDIPTR146
  [23:16] TINT170, [15:8] TINT169, [7:0] TINT168
0xC00 ICDICFR0
  [2n+1] SW{n}_1 (n=0..15), [2n] SW{n}_0 (n=0..15)
0xC04 ICDICFR1
  [7] CTIIRQ0_1, [6] CTIIRQ0_0, [5] COMMTX0_1, [4] COMMTX0_0, [3] COMMRX0_1, [2] COMMRX0_0, [1] PMUIRQ0_1, [0] PMUIRQ0_0
0xC08 ICDICFR2
  [2n+19] DMAINT{n}_1 (n=0..6), [2n+18] DMAINT{n}_0 (n=0..6), [17] PL310ERR_1, [16] PL310ERR_0, [2n+1] IRQ{n}_1 (n=0..7), [2n] IRQ{n}_0 (n=0..7)
0xC0C ICDICFR3
  [19] DMAERR_1, [18] DMAERR_0, [2n-13] DMAINT{n}_1 (n=7..15), [2n-14] DMAINT{n}_0 (n=7..15)
0xC10 ICDICFR4
  [31] S0_VFIELD0_1, [30] S0_VFIELD0_0, [29] GR3_VLINE0_1, [28] GR3_VLINE0_0, [27] S0_VSYNCERR0_1, [26] S0_VSYNCERR0_0, [25] S0_LO_VSYNC0_1, [24] S0_LO_VSYNC0_0, [23] S0_VI_VSYNC0_1, [22] S0_VI_VSYNC0_0, [21] USBI1_1, [20] USBI1_0, [19] USBI0_1, [18] USBI0_0
0xC14 ICDICFR5
  [31] OIR_VFIELD0_1, [30] OIR_VFIELD0_0, [29] OIR_VSYNCERR0_1, [28] OIR_VSYNCERR0_0, [27] OIR_LO_VSYNC0_1, [26] OIR_LO_VSYNC0_0, [25] OIR_VI_VSYNC0_1, [24] OIR_VI_VSYNC0_0, [23] S1_WLINE0_1, [22] S1_WLINE0_0, [21] IV4_VBUFERR0_1, [20] IV4_VBUFERR0_0, [19] IV2_VBUFERR0_1, [18] IV2_VBUFERR0_0, [17] S1_VFIELD0_1, [16] S1_VFIELD0_0, [15] S1_VSYNCERR0_1, [14] S1_VSYNCERR0_0, [13] S1_LO_VSYNC0_1, [12] S1_LO_VSYNC0_0, [11] S1_VI_VSYNC0_1, [10] S1_VI_VSYNC0_0, [9] S0_WLINE0_1, [8] S0_WLINE0_0, [7] IV6_VBUFERR0_1, [6] IV6_VBUFERR0_0, [5] IV5_VBUFERR0_1, [4] IV5_VBUFERR0_0, [3] IV3_VBUFERR0_1, [2] IV3_VBUFERR0_0, [1] IV1_VBUFERR0_1, [0] IV1_VBUFERR0_0
0xC18 ICDICFR6
  [31] S1_VSYNCERR1_1, [30] S1_VSYNCERR1_0, [29] S1_LO_VSYNC1_1, [28] S1_LO_VSYNC1_0, [27] S1_VI_VSYNC1_1, [26] S1_VI_VSYNC1_0, [25] S0_WLINE1_1, [24] S0_WLINE1_0, [23] IV6_VBUFERR1_1, [22] IV6_VBUFERR1_0, [21] IV5_VBUFERR1_1, [20] IV5_VBUFERR1_0, [19] IV3_VBUFERR1_1, [18] IV3_VBUFERR1_0, [17] IV1_VBUFERR1_1, [16] IV1_VBUFERR1_0, [15] S0_VFIELD1_1, [14] S0_VFIELD1_0, [13] GR3_VLINE1_1, [12] GR3_VLINE1_0, [11] S0_VSYNCERR1_1, [10] S0_VSYNCERR1_0, [9] S0_LO_VSYNC1_1, [8] S0_LO_VSYNC1_0, [7] S0_VI_VSYNC1_1, [6] S0_VI_VSYNC1_0, [5] OIR_WLINE0_1, [4] OIR_WLINE0_0, [3] IV8_VBUFERR0_1, [2] IV8_VBUFERR0_0, [1] IV7_VBUFERR0_1, [0] IV7_VBUFERR0_0
0xC1C ICDICFR7
  [31] JDTI_1, [30] JDTI_0, [29] JEDI_1, [28] JEDI_0, [27] IMR2I1_1, [26] IMR2I1_0, [25] IMR2I0_1, [24] IMR2I0_0, [23] IMRDI_1, [22] IMRDI_0, [21] OIR_WLINE1_1, [20] OIR_WLINE1_0, [19] IV8_VBUFERR1_1, [18] IV8_VBUFERR1_0, [17] IV7_VBUFERR1_1, [16] IV7_VBUFERR1_0, [15] OIR_VFIELD1_1, [14] OIR_VFIELD1_0, [13] OIR_VLINE1_1, [12] OIR_VLINE1_0, [11] OIR_LO_VSYNC1_1, [10] OIR_LO_VSYNC1_0, [9] OIR_VI_VSYNC1_1, [8] OIR_VI_VSYNC1_0, [7] S1_WLINE1_1, [6] S1_WLINE1_0, [5] IV4_VBUFERR1_1, [4] IV4_VBUFERR1_0, [3] IV2_VBUFERR1_1, [2] IV2_VBUFERR1_0, [1] S1_VFIELD1_1, [0] S1_VFIELD1_0
0xC20 ICDICFR8
  [31] TGI0V_1, [30] TGI0V_0, [29] TGI0D_1, [28] TGI0D_0, [27] TGI0C_1, [26] TGI0C_0, [25] TGI0B_1, [24] TGI0B_0, [23] TGI0A_1, [22] TGI0A_0, [21] ITI_1, [20] ITI_0, [19] WTOUT_1, [18] WTOUT_0, [17] CMI_1, [16] CMI_0, [15] OSTM1TINT_1, [14] OSTM1TINT_0, [13] OSTM0TINT_1, [12] OSTM0TINT_0, [2n+5] INT{n}_1 (n=0..3), [2n+4] INT{n}_0 (n=0..3), [3] CMP1_1, [2] CMP1_0, [1] CMP0_1, [0] CMP0_0
0xC24 ICDICFR9
  [31] TGI4A_1, [30] TGI4A_0, [29] TGI3V_1, [28] TGI3V_0, [27] TGI3D_1, [26] TGI3D_0, [25] TGI3C_1, [24] TGI3C_0, [23] TGI3B_1, [22] TGI3B_0, [21] TGI3A_1, [20] TGI3A_0, [19] TGI2U_1, [18] TGI2U_0, [17] TGI2V_1, [16] TGI2V_0, [15] TGI2B_1, [14] TGI2B_0, [13] TGI2A_1, [12] TGI2A_0, [11] TGI1U_1, [10] TGI1U_0, [9] TGI1V_1, [8] TGI1V_0, [7] TGI1B_1, [6] TGI1B_0, [5] TGI1A_1, [4] TGI1A_0, [3] TGI0F_1, [2] TGI0F_0, [1] TGI0E_1, [0] TGI0E_0
0xC28 ICDICFR10
  [31] SSII1_1, [30] SSII1_0, [29] SSITXI0_1, [28] SSITXI0_0, [27] SSIRXI0_1, [26] SSIRXI0_0, [25] SSII0_1, [24] SSII0_0, [23] LMTI_1, [22] LMTI_0, [21] ADI_1, [20] ADI_0, [2n+13] SGDEI{n}_1 (n=0..3), [2n+12] SGDEI{n}_0 (n=0..3), [11] CMI2_1, [10] CMI2_0, [9] CMI1_1, [8] CMI1_0, [7] TGI4V_1, [6] TGI4V_0, [5] TGI4D_1, [4] TGI4D_0, [3] TGI4C_1, [2] TGI4C_0, [1] TGI4B_1, [0] TGI4B_0
0xC2C ICDICFR11
  [31] INTIICTI0_1, [30] INTIICTI0_0, [29] INTIICRI0_1, [28] INTIICRI0_0, [27] INTIICTEI0_1, [26] INTIICTEI0_0, [25] SPDIFI_1, [24] SPDIFI_0, [23] SSITXI5_1, [22] SSITXI5_0, [21] SSIRXI5_1, [20] SSIRXI5_0, [19] SSII5_1, [18] SSII5_0, [17] SSIRTI4_1, [16] SSIRTI4_0, [15] SSII4_1, [14] SSII4_0, [13] SSITXI3_1, [12] SSITXI3_0, [11] SSIRXI3_1, [10] SSIRXI3_0, [9] SSII3_1, [8] SSII3_0, [7] SSIRTI2_1, [6] SSIRTI2_0, [5] SSII2_1, [4] SSII2_0, [3] SSITXI1_1, [2] SSITXI1_0, [1] SSIRXI1_1, [0] SSIRXI1_0
0xC30 ICDICFR12
  [31] INTIICTI2_1, [30] INTIICTI2_0, [29] INTIICRI2_1, [28] INTIICRI2_0, [27] INTIICTEI2_1, [26] INTIICTEI2_0, [25] INTIICTMOI1_1, [24] INTIICTMOI1_0, [23] INTIICALI1_1, [22] INTIICALI1_0, [21] INTIICNAKI1_1, [20] INTIICNAKI1_0, [19] INTIICSTI1_1, [18] INTIICSTI1_0, [17] INTIICSPI1_1, [16] INTIICSPI1_0, [15] INTIICTI1_1, [14] INTIICTI1_0, [13] INTIICRI1_1, [12] INTIICRI1_0, [11] INTIICTEI1_1, [10] INTIICTEI1_0, [9] INTIICTMOI0_1, [8] INTIICTMOI0_0, [7] INTIICALI0_1, [6] INTIICALI0_0, [5] INTIICNAKI0_1, [4] INTIICNAKI0_0, [3] INTIICSTI0_1, [2] INTIICSTI0_0, [1] INTIICSPI0_1, [0] INTIICSPI0_0
0xC34 ICDICFR13
  [31] RXI0_1, [30] RXI0_0, [29] ERI0_1, [28] ERI0_0, [27] BRI0_1, [26] BRI0_0, [25] INTIICTMOI3_1, [24] INTIICTMOI3_0, [23] INTIICALI3_1, [22] INTIICALI3_0, [21] INTIICNAKI3_1, [20] INTIICNAKI3_0, [19] INTIICSTI3_1, [18] INTIICSTI3_0, [17] INTIICSPI3_1, [16] INTIICSPI3_0, [15] INTIICTI3_1, [14] INTIICTI3_0, [13] INTIICRI3_1, [12] INTIICRI3_0, [11] INTIICTEI3_1, [10] INTIICTEI3_0, [9] INTIICTMOI2_1, [8] INTIICTMOI2_0, [7] INTIICALI2_1, [6] INTIICALI2_0, [5] INTIICNAKI2_1, [4] INTIICNAKI2_0, [3] INTIICSTI2_1, [2] INTIICSTI2_0, [1] INTIICSPI2_1, [0] INTIICSPI2_0
0xC38 ICDICFR14
  [8n-1] RXI{n}_1 (n=1..4), [8n-2] RXI{n}_0 (n=1..4), [8n-3] ERI{n}_1 (n=1..4), [8n-4] ERI{n}_0 (n=1..4), [8n-5] BRI{n}_1 (n=1..4), [8n-6] BRI{n}_0 (n=1..4), [8n+1] TXI{n}_1 (n=0..3), [8n] TXI{n}_0 (n=0..3)
0xC3C ICDICFR15
  [31] INTRCAN0REC_1, [30] INTRCAN0REC_0, [29] INTRCANGRECC_1, [28] INTRCANGRECC_0, [27] INTRCANGERR_1, [26] INTRCANGERR_0, [8n-31] TXI{n}_1 (n=4..7), [8n-32] TXI{n}_0 (n=4..7), [23] RXI7_1, [22] RXI7_0, [21] ERI7_1, [20] ERI7_0, [19] BRI7_1, [18] BRI7_0, [15] RXI6_1, [14] RXI6_0, [13] ERI6_1, [12] ERI6_0, [11] BRI6_1, [10] BRI6_0, [7] RXI5_1, [6] RXI5_0, [5] ERI5_1, [4] ERI5_0, [3] BRI5_1, [2] BRI5_0
0xC40 ICDICFR16
  [31] SPRI0_1, [30] SPRI0_0, [29] SPEI0_1, [28] SPEI0_0, [6n+3] INTRCAN{n}TRX_1 (n=0..4), [6n+2] INTRCAN{n}TRX_0 (n=0..4), [6n+1] INTRCAN{n}ERR_1 (n=0..4), [6n] INTRCAN{n}ERR_0 (n=0..4), [6n-1] INTRCAN{n}REC_1 (n=1..4), [6n-2] INTRCAN{n}REC_0 (n=1..4)
0xC44 ICDICFR17
  [31] IEBBTSTA_1, [30] IEBBTSTA_0, [29] IEBBTERR_1, [28] IEBBTERR_0, [27] IEBBTD_1, [26] IEBBTD_0, [6n+1] SPTI{n}_1 (n=0..4), [6n] SPTI{n}_0 (n=0..4), [6n-1] SPRI{n}_1 (n=1..4), [6n-2] SPRI{n}_0 (n=1..4), [6n-3] SPEI{n}_1 (n=1..4), [6n-4] SPEI{n}_0 (n=1..4)
0xC48 ICDICFR18
  [31] SDHI0_0_1, [30] SDHI0_0_0, [29] SDHI0_3_1, [28] SDHI0_3_0, [27] MMC2_1, [26] MMC2_0, [25] MMC1_1, [24] MMC1_0, [23] MMC0_1, [22] MMC0_0, [21] FLTREQ1I_1, [20] FLTREQ1I_0, [19] FLTREQ0I_1, [18] FLTREQ0I_0, [17] FLTENDI_1, [16] FLTENDI_0, [15] FLSTE_1, [14] FLSTE_0, [13] IREADY_1, [12] IREADY_0, [11] IBUF_1, [10] IBUF_0, [9] ISEC_1, [8] ISEC_0, [7] ITARG_1, [6] ITARG_0, [5] IERR_1, [4] IERR_0, [3] ISY_1, [2] ISY_0, [1] IEBBTV_1, [0] IEBBTV_0
0xC4C ICDICFR19
  [31] SCUFUI2_1, [30] SCUFUI2_0, [29] SCUFUI1_1, [28] SCUFUI1_0, [27] SCUFUI0_1, [26] SCUFUI0_0, [2n+19] SCUFDI{n}_1 (n=0..3), [2n+18] SCUFDI{n}_0 (n=0..3), [17] SCUAI1_1, [16] SCUAI1_0, [15] SCUAI0_1, [14] SCUAI0_0, [13] CUP_1, [12] CUP_0, [11] PRD_1, [10] PRD_0, [9] ARM_1, [8] ARM_0, [7] SDHI1_1_1, [6] SDHI1_1_0, [5] SDHI1_0_1, [4] SDHI1_0_0, [3] SDHI1_3_1, [2] SDHI1_3_0, [1] SDHI0_1_1, [0] SDHI0_1_0
0xC50 ICDICFR20
  [31] LINI1_INT_T_1, [30] LINI1_INT_T_0, [29] LINI0_INT_M_1, [28] LINI0_INT_M_0, [27] LINI0_INT_S_1, [26] LINI0_INT_S_0, [25] LINI0_INT_R_1, [24] LINI0_INT_R_0, [23] LINI0_INT_T_1, [22] LINI0_INT_T_0, [17] DRC1_1, [16] DRC1_0, [15] DRC0_1, [14] DRC0_0, [13] MLB_SINT_1, [12] MLB_SINT_0, [11] MLB_CINT_1, [10] MLB_CINT_0, [2n+3] SCUDVI{n}_1 (n=0..3), [2n+2] SCUDVI{n}_0 (n=0..3), [1] SCUFUI3_1, [0] SCUFUI3_0
0xC54 ICDICFR21
  [31] ERI1_1, [30] ERI1_0, [29] TEI0_1, [28] TEI0_0, [27] TXI0_1, [26] TXI0_0, [25] RXI0_1, [24] RXI0_0, [23] ERI0_1, [22] ERI0_0, [5] LINI1_INT_M_1, [4] LINI1_INT_M_0, [3] LINI1_INT_S_1, [2] LINI1_INT_S_0, [1] LINI1_INT_R_1, [0] LINI1_INT_R_0
0xC58 ICDICFR22
  [25] CEUI_1, [24] CEUI_0, [15] ETHERI_1, [14] ETHERI_0, [13] AVBI_MAC_1, [12] AVBI_MAC_0, [11] AVBI_MANAGE_1, [10] AVBI_MANAGE_0, [9] AVBI_ERROR_1, [8] AVBI_ERROR_0, [7] AVBI_DATA_1, [6] AVBI_DATA_0, [5] TEI1_1, [4] TEI1_0, [3] TXI1_1, [2] TXI1_0, [1] RXI1_1, [0] RXI1_0
0xC5C ICDICFR23
  [31] X2HPERI1_ERRINT_1, [30] X2HPERI1_ERRINT_0, [29] H2XIC1_ERRINT_1, [28] H2XIC1_ERRINT_0, [27] H2XMLB_ERRINT_1, [26] H2XMLB_ERRINT_0
0xC60 ICDICFR24
  [29] PFVEI1_1, [28] PFVEI1_0, [27] OFFI1_1, [26] OFFI1_0, [25] IFEI1_1, [24] IFEI1_0, [23] PFVEI0_1, [22] PFVEI0_0, [21] OFFI0_1, [20] OFFI0_0, [19] IFEI0_1, [18] IFEI0_0, [17] PRRI_1, [16] PRRI_0, [15] X2HSPI2_ERRINT_1, [14] X2HSPI2_ERRINT_0, [13] X2HSPI1_ERRINT_1, [12] X2HSPI1_ERRINT_0, [11] X2HBSC_ERRINT_1, [10] X2HBSC_ERRINT_0, [9] X2HDBGR_ERRINT_1, [8] X2HDBGR_ERRINT_0, [7] X2HPERI67_ERRINT_1, [6] X2HPERI67_ERRINT_0, [5] X2HPERI5_ERRINT_1, [4] X2HPERI5_ERRINT_0, [3] X2HPERI34_ERRINT_1, [2] X2HPERI34_ERRINT_0, [1] X2HPERI2_ERRINT_1, [0] X2HPERI2_ERRINT_0
0xC64 ICDICFR25
0xC68 ICDICFR26
  [2n+1] TINT{n}_1 (n=0..15), [2n] TINT{n}_0 (n=0..15)
0xC6C ICDICFR27
  [2n-31] TINT{n}_1 (n=16..31), [2n-32] TINT{n}_0 (n=16..31)
0xC70 ICDICFR28
  [2n-63] TINT{n}_1 (n=32..47), [2n-64] TINT{n}_0 (n=32..47)
0xC74 ICDICFR29
  [2n-95] TINT{n}_1 (n=48..63), [2n-96] TINT{n}_0 (n=48..63)
0xC78 ICDICFR30
  [2n-127] TINT{n}_1 (n=64..79), [2n-128] TINT{n}_0 (n=64..79)
0xC7C ICDICFR31
  [2n-159] TINT{n}_1 (n=80..95), [2n-160] TINT{n}_0 (n=80..95)
0xC80 ICDICFR32
  [2n-191] TINT{n}_1 (n=96..111), [2n-192] TINT{n}_0 (n=96..111)
0xC84 ICDICFR33
  [2n-223] TINT{n}_1 (n=112..127), [2n-224] TINT{n}_0 (n=112..127)
0xC88 ICDICFR34
  [2n-255] TINT{n}_1 (n=128..143), [2n-256] TINT{n}_0 (n=128..143)
0xC8C ICDICFR35
  [2n-287] TINT{n}_1 (n=144..159), [2n-288] TINT{n}_0 (n=144..159)
0xC90 ICDICFR36
  [2n-319] TINT{n}_1 (n=160..170), [2n-320] TINT{n}_0 (n=160..170)
0xD00 PPI_STATUS
{0xD04+4i} SPI_STATUS{i} (i=0..16)
0xF00 ICDSGIR
  [25:24] TargetListFilter, [23:16] CPUTargetList, [15] SATT, [3:0] SGIINTID
0x1000 ICCICR
  [4] SBPR, [3] FIQEn, [2] AckCtl, [1] EnableNS, [0] EnableS
0x1004 ICCPMR
  [7:0] Priority
0x1008 ICCBPR
  [2:0] Binarypoint
0x100C ICCIAR
  [12:10] CPUID, [9:0] ACKINTID
0x1010 ICCEOIR
  [12:10] CPUID, [9:0] EOIINTID
0x1014 ICCRPR
  [7:0] Priority
0x1018 ICCHPIR
  [12:10] CPUID, [9:0] PENDINTID
0x101C ICCABPR
  [2:0] Binarypoint
0x10FC ICCIIDR
  [31:20] ProductID, [19:16] Architecture_version, [15:12] Revision, [11:0] Implementer
0x14DEE800 ICR0 16-bit
  [15] NMIL, [8] NMIE, [1] NMIF
0x14DEE802 ICR1 16-bit
  [15] IRQ71S, [14] IRQ70S, [13] IRQ61S, [12] IRQ60S, [11] IRQ51S, [10] IRQ50S, [9] IRQ41S, [8] IRQ40S, [7] IRQ31S, [6] IRQ30S, [5] IRQ21S, [4] IRQ20S, [3] IRQ11S, [2] IRQ10S, [1] IRQ01S, [0] IRQ00S
0x14DEE804 IRQRR 16-bit
  [n] IRQ{n}F (n=0..7)
